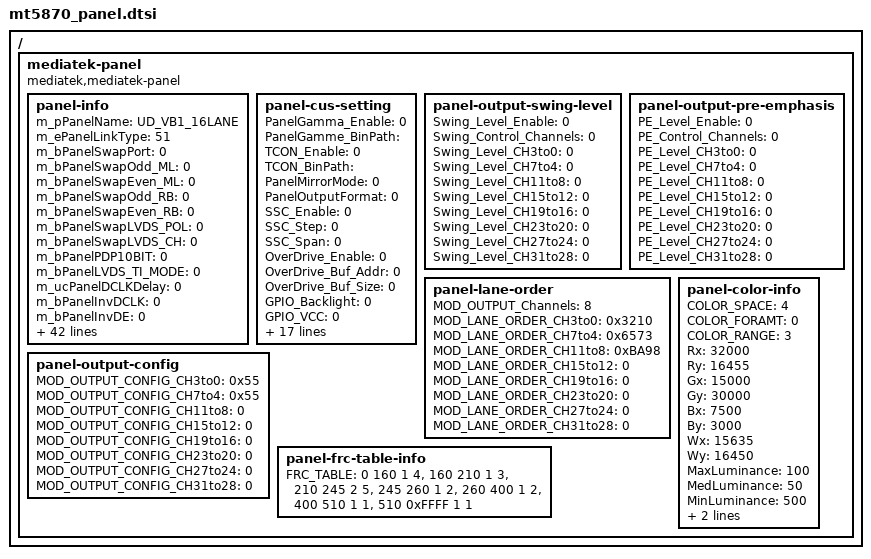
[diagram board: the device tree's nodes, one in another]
// SPDX-License-Identifier: (GPL-2.0 OR BSD-3-Clause)
/*
 * Copyright (c) 2020 MediaTek Inc.
 */

/ {
	mediatek-panel {
		compatible = "mediatek,mediatek-panel";
		panel-info {
			m_pPanelName = "UD_VB1_16LANE";
			m_ePanelLinkType = <51>;

			m_bPanelSwapPort = <0>;
			m_bPanelSwapOdd_ML = <0>;
			m_bPanelSwapEven_ML = <0>;
			m_bPanelSwapOdd_RB = <0>;
			m_bPanelSwapEven_RB = <0>;
			m_bPanelSwapLVDS_POL = <0>;
			m_bPanelSwapLVDS_CH = <0>;
			m_bPanelPDP10BIT = <0>;
			m_bPanelLVDS_TI_MODE = <0>;

			m_ucPanelDCLKDelay = <0>;
			m_bPanelInvDCLK = <0>;
			m_bPanelInvDE = <0>;
			m_bPanelInvHSync = <0>;
			m_bPanelInvVSync = <0>;

			m_wPanelOnTiming1 = <30>;
			m_wPanelOnTiming2 = <200>;
			m_wPanelOffTiming1 = <220>;
			m_wPanelOffTiming2 = <10>;

			m_ucPanelHSyncWidth = <30>;
			m_ucPanelHSyncBackPorch = <80>;

			m_ucPanelVSyncWidth = <2>;
			m_ucPanelVBackPorch = <40>;

			m_wPanelHStart = <110>;
			m_wPanelVStart = <98>;

			m_wPanelWidth = <3840>;
			m_wPanelHeight = <2160>;

			m_wPanelMaxHTotal = <4500>;
			m_wPanelHTotal = <4400>;
			m_wPanelMinHTotal = <4300>;

			m_wPanelMaxVTotal = <2360>;
			m_wPanelVTotal = <2260>;
			m_wPanelMinVTotal = <2160>;

			m_dwPanelMaxDCLK = <610>;
			m_dwPanelDCLK = <600>;
			m_dwPanelMinDCLK = <590>;

			m_ucTiBitMode = <2>;
			m_ucOutputFormatBitMode = <0>;

			m_u16LVDSTxSwapValue = <0xFFFF>;
			m_bPanelSwapOdd_RG = <0>;
			m_bPanelSwapEven_RG = <0>;
			m_bPanelSwapOdd_GB = <0>;
			m_bPanelSwapEven_GB = <0>;
			m_bPanelNoiseDith = < 1>;

			u32PeriodPWM = <0xFFFF>;
			u32DutyPWM = <0x3FFF>;
			u16DivPWM = <0x00>;
			bPolPWM = <0>;
			u16MaxPWMvalue = <0xFFFF>;
			u16TypPWMvalue = <0x6D00>;
			u16MinPWMvalue = <0x2000>;
			u16PWMPort = <0>;

			m_bVRR_en = <0>;
			m_wVRR_min = <30>;
			m_wVRR_max = <120>;

		};
		panel-cus-setting {
			PanelGamma_Enable = <0>;
			PanelGamme_BinPath = "";
			TCON_Enable = <0>;
			TCON_BinPath = "";
			PanelMirrorMode = <0>;
			PanelOutputFormat = <0>;
			SSC_Enable = <0>;
			SSC_Step = <0>;
			SSC_Span = <0>;
			OverDrive_Enable = <0>;
			OverDrive_Buf_Addr = <0>;
			OverDrive_Buf_Size = <0>;
			GPIO_Backlight = <0>;
			GPIO_VCC = <0>;
			M_delta = <4>;
			CustomerColorPrimaries = <0>;
			SourceWx = <15635>;
			SourceWy = <16450>;
			VIDEO_GFX_DISPLAY_MODE = <0>;
			OSD_Height = <0>;
			OSD_Width = <0>;
			OSD_HsyncStart = <0>;
			OSD_HsyncEnd = <0>;
			OSD_HDEStart = <0>;
			OSD_HDEEnd = <0>;
			OSD_HTotal = <0>;
			OSD_VsyncStart = <0>;
			OSD_VsyncEnd = <0>;
			OSD_VDEStart = <0>;
			OSD_VDEEnd = <0>;
			OSD_VTotal = <0>;
		};
		panel-output-swing-level {
			Swing_Level_Enable = <0>;
			Swing_Control_Channels = <0>;
			Swing_Level_CH3to0 = <0>;
			Swing_Level_CH7to4 = <0>;
			Swing_Level_CH11to8 = <0>;
			Swing_Level_CH15to12 = <0>;
			Swing_Level_CH19to16 = <0>;
			Swing_Level_CH23to20 = <0>;
			Swing_Level_CH27to24 = <0>;
			Swing_Level_CH31to28 = <0>;
		};
		panel-output-pre-emphasis {
			PE_Level_Enable = <0>;
			PE_Control_Channels = <0>;
			PE_Level_CH3to0 = <0>;
			PE_Level_CH7to4 = <0>;
			PE_Level_CH11to8 = <0>;
			PE_Level_CH15to12 = <0>;
			PE_Level_CH19to16 = <0>;
			PE_Level_CH23to20 = <0>;
			PE_Level_CH27to24 = <0>;
			PE_Level_CH31to28 = <0>;
		};
		panel-lane-order {
			MOD_OUTPUT_Channels = <8>;
			MOD_LANE_ORDER_CH3to0 = <0x3210>;
			MOD_LANE_ORDER_CH7to4 = <0x6573>;
			MOD_LANE_ORDER_CH11to8 = <0xBA98>;
			MOD_LANE_ORDER_CH15to12 = <0>;
			MOD_LANE_ORDER_CH19to16 = <0>;
			MOD_LANE_ORDER_CH23to20 = <0>;
			MOD_LANE_ORDER_CH27to24 = <0>;
			MOD_LANE_ORDER_CH31to28 = <0>;
		};
		panel-output-config {
			MOD_OUTPUT_CONFIG_CH3to0 = <0x55>;
			MOD_OUTPUT_CONFIG_CH7to4 = <0x55>;
			MOD_OUTPUT_CONFIG_CH11to8 = <0>;
			MOD_OUTPUT_CONFIG_CH15to12 = <0>;
			MOD_OUTPUT_CONFIG_CH19to16 = <0>;
			MOD_OUTPUT_CONFIG_CH23to20 = <0>;
			MOD_OUTPUT_CONFIG_CH27to24 = <0>;
			MOD_OUTPUT_CONFIG_CH31to28 = <0>;
		};
		panel-frc-table-info {
			FRC_TABLE =
			<0 160 1 4>,
			<160 210 1 3>,
			<210 245 2 5>,
			<245 260 1 2>,
			<260 400 1 2>,
			<400 510 1 1>,
			<510 0xFFFF 1 1>;
		};
		panel-color-info {
			COLOR_SPACE = <4>;
			COLOR_FORAMT = <0>;
			COLOR_RANGE = <3>;
			Rx = <32000>;
			Ry = <16455>;
			Gx = <15000>;
			Gy = <30000>;
			Bx = <7500>;
			By = <3000>;
			Wx = <15635>;
			Wy = <16450>;
			MaxLuminance = <100>;
			MedLuminance = <50>;
			MinLuminance = <500>;
			LinearRGB = <1>;
			HDRPanelNits = <399>;
		};
	};
};
